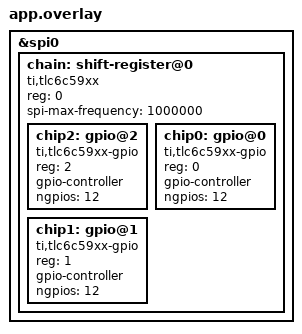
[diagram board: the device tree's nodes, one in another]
/*
 * SPDX-FileCopyrightText: Copyright The Zephyr Project Contributors
 * SPDX-License-Identifier: Apache-2.0
 */

&spi0 {
	chain: shift-register@0 {
		compatible = "ti,tlc6c59xx";
		reg = <0>;
		spi-max-frequency = <1000000>;
		#address-cells = <1>;
		#size-cells = <0>;

		/* Deliberately not in chain order: reg determines the position. */
		chip2: gpio@2 {
			compatible = "ti,tlc6c59xx-gpio";
			reg = <2>;
			gpio-controller;
			#gpio-cells = <2>;
			ngpios = <12>;
		};

		chip0: gpio@0 {
			compatible = "ti,tlc6c59xx-gpio";
			reg = <0>;
			gpio-controller;
			#gpio-cells = <2>;
			ngpios = <12>;
		};

		chip1: gpio@1 {
			compatible = "ti,tlc6c59xx-gpio";
			reg = <1>;
			gpio-controller;
			#gpio-cells = <2>;
			ngpios = <12>;
		};
	};
};
